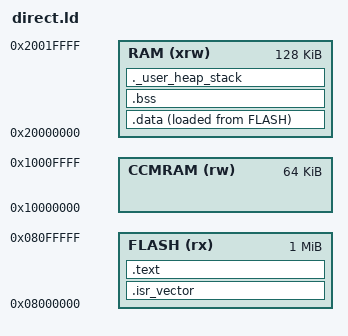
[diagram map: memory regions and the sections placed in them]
/*
*****************************************************************************
**
**  File        : stm32_flash.ld
**
**  Abstract    : Linker script for STM32F417IG Device with
**                1024KByte FLASH, 128KByte RAM
**
**                Set heap size, stack size and stack location according
**                to application requirements.
**
**                Set memory bank area and size if external memory is used.
**
**  Target      : STMicroelectronics STM32
**
**  Environment : Atollic TrueSTUDIO(R)
**
**  Distribution: The file is distributed “as is,” without any warranty
**                of any kind.
**
**  (c)Copyright Atollic AB.
**  You may use this file as-is or modify it according to the needs of your
**  project. This file may only be built (assembled or compiled and linked)
**  using the Atollic TrueSTUDIO(R) product. The use of this file together
**  with other tools than Atollic TrueSTUDIO(R) is not permitted.
**
*****************************************************************************
*/

/* Entry Point */
ENTRY(Reset_Handler)

/* Highest address of the user mode stack */
_estack = 0x20020000;    /* end of 128K RAM */

/* Generate a link error if heap and stack don't fit into RAM */
_Min_Heap_Size = MIN_HEAP_SIZE;      /* required amount of heap  */
_Min_Stack_Size = MIN_STACK_SIZE; /* required amount of stack */

/* Specify the memory areas */
MEMORY
{
  FLASH (rx)      : ORIGIN = 0x08000000, LENGTH = 1024K
  RAM (xrw)       : ORIGIN = 0x20000000, LENGTH = 128K
  CCMRAM (rw)     : ORIGIN = 0x10000000, LENGTH = 64K
}

/* Define output sections */
SECTIONS
{
  /* The startup code goes first into FLASH */
  .isr_vector :
  {
    . = ALIGN(4);
    KEEP(*(.isr_vector)) /* Startup code */
    . = ALIGN(4);
  } >FLASH

  /* The program code and other data goes into FLASH */
  .text :
  {
    . = ALIGN(4);
    *(.text)           /* .text sections (code) */
    *(.text*)          /* .text* sections (code) */
    . = ALIGN(4);
    _etext = .;        /* define a global symbols at end of code */
  } >FLASH

  /* used by the startup to initialize data */
  _sidata = LOADADDR(.data);

  /* Initialized data sections goes into RAM, load LMA copy after code */
  .data : 
  {
    . = ALIGN(4);
    _sdata = .;        /* create a global symbol at data start */
    *(.data)           /* .data sections */
    *(.data*)          /* .data* sections */
    . = ALIGN(4);
    _edata = .;        /* define a global symbol at data end */
  } >RAM AT> FLASH
  
  /* Uninitialized data section */
  . = ALIGN(4);
  .bss :
  {
    /* This is used by the startup in order to initialize the .bss secion */
    _sbss = .;         /* define a global symbol at bss start */
    __bss_start__ = _sbss;
    *(.bss)
    *(.bss*)
    *(COMMON)
    . = ALIGN(4);
    _ebss = .;         /* define a global symbol at bss end */
    __bss_end__ = _ebss;
  } >RAM

  /* User_heap_stack section, used to check that there is enough RAM left */
  ._user_heap_stack :
  {
    . = ALIGN(4);
    PROVIDE ( end = . );
    PROVIDE ( _end = . );
    . = . + _Min_Heap_Size;
    . = . + _Min_Stack_Size;
    . = ALIGN(4);
  } >RAM

  .ARM.attributes 0 : { *(.ARM.attributes) }
}
